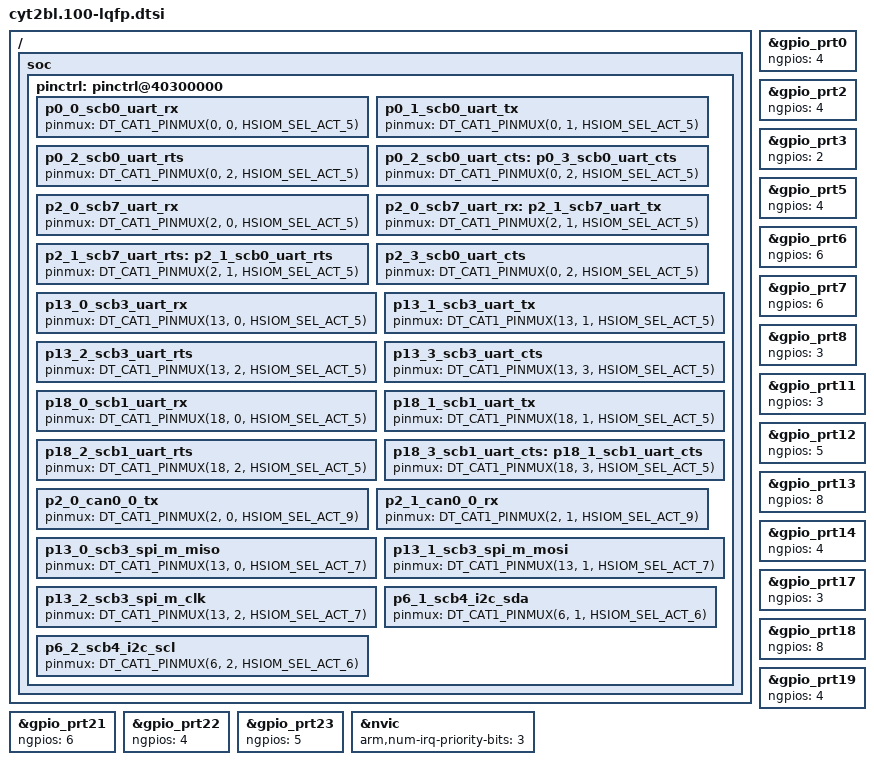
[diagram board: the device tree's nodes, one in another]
/*
 * Copyright (c) 2026 Infineon Technologies AG,
 * or an affiliate of Infineon Technologies AG.
 *
 * SPDX-License-Identifier: Apache-2.0
 */

#include "cyt2bl.dtsi"
#include <arm/armv7-m.dtsi>
#include <zephyr/dt-bindings/gpio/gpio.h>
#include <zephyr/dt-bindings/pinctrl/ifx_cat1-pinctrl.h>


/ {

        soc {
                /delete-node/ gpio@40310080; // gpio_prt1
                /delete-node/ gpio@40310200; // gpio_prt4
                /delete-node/ gpio@40310480; // gpio_prt9
                /delete-node/ gpio@40310500; // gpio_prt10
                /delete-node/ gpio@40310780; // gpio_prt15
                /delete-node/ gpio@40310800; // gpio_prt16
                /delete-node/ gpio@40310A00; // gpio_prt20
				pinctrl: pinctrl@40300000 {
					/omit-if-no-ref/ p0_0_scb0_uart_rx: p0_0_scb0_uart_rx {
								pinmux = <DT_CAT1_PINMUX(0, 0,	HSIOM_SEL_ACT_5)>;
					};
					/omit-if-no-ref/ p0_1_scb0_uart_tx: p0_1_scb0_uart_tx {
								pinmux = <DT_CAT1_PINMUX(0, 1,	HSIOM_SEL_ACT_5)>;
					};
					/omit-if-no-ref/ p0_2_scb0_uart_rts: p0_2_scb0_uart_rts {
								pinmux = <DT_CAT1_PINMUX(0, 2,	HSIOM_SEL_ACT_5)>;
					};
					/omit-if-no-ref/ p0_2_scb0_uart_cts: p0_3_scb0_uart_cts {
								pinmux = <DT_CAT1_PINMUX(0, 2,	HSIOM_SEL_ACT_5)>;
					};
					/omit-if-no-ref/ p2_0_scb7_uart_rx: p2_0_scb7_uart_rx {
								pinmux = <DT_CAT1_PINMUX(2, 0,	HSIOM_SEL_ACT_5)>;
					};
                    /omit-if-no-ref/ p2_0_scb7_uart_rx: p2_1_scb7_uart_tx {
								pinmux = <DT_CAT1_PINMUX(2, 1,	HSIOM_SEL_ACT_5)>;
					};
                    /omit-if-no-ref/ p2_1_scb7_uart_rts: p2_1_scb0_uart_rts {
								pinmux = <DT_CAT1_PINMUX(2, 1,	HSIOM_SEL_ACT_5)>;
					};
					/omit-if-no-ref/ p2_3_scb0_uart_cts: p2_3_scb0_uart_cts {
								pinmux = <DT_CAT1_PINMUX(0, 2,	HSIOM_SEL_ACT_5)>;
					};
					/omit-if-no-ref/ p13_0_scb3_uart_rx: p13_0_scb3_uart_rx {
								pinmux = <DT_CAT1_PINMUX(13, 0, HSIOM_SEL_ACT_5)>;
					};
					/omit-if-no-ref/ p13_1_scb3_uart_tx: p13_1_scb3_uart_tx {
								pinmux = <DT_CAT1_PINMUX(13, 1, HSIOM_SEL_ACT_5)>;
					};
					/omit-if-no-ref/ p13_2_scb3_uart_rts: p13_2_scb3_uart_rts {
								pinmux = <DT_CAT1_PINMUX(13, 2, HSIOM_SEL_ACT_5)>;
					};
					/omit-if-no-ref/ p13_3_scb3_uart_cts: p13_3_scb3_uart_cts {
								pinmux = <DT_CAT1_PINMUX(13, 3, HSIOM_SEL_ACT_5)>;
					};


					/omit-if-no-ref/ p18_0_scb1_uart_rx: p18_0_scb1_uart_rx {
								pinmux = <DT_CAT1_PINMUX(18, 0, HSIOM_SEL_ACT_5)>;
					};
					/omit-if-no-ref/ p18_1_scb1_uart_tx: p18_1_scb1_uart_tx {
								pinmux = <DT_CAT1_PINMUX(18, 1, HSIOM_SEL_ACT_5)>;
					};
					/omit-if-no-ref/ p18_2_scb1_uart_rts: p18_2_scb1_uart_rts {
								pinmux = <DT_CAT1_PINMUX(18, 2, HSIOM_SEL_ACT_5)>;
					};
					/omit-if-no-ref/ p18_3_scb1_uart_cts: p18_1_scb1_uart_cts {
								pinmux = <DT_CAT1_PINMUX(18, 3, HSIOM_SEL_ACT_5)>;
					};


					/omit-if-no-ref/ p2_0_can0_0_tx: p2_0_can0_0_tx {
								pinmux = <DT_CAT1_PINMUX(2, 0, HSIOM_SEL_ACT_9)>;
					};

					/omit-if-no-ref/ p2_1_can0_0_rx: p2_1_can0_0_rx {
								pinmux = <DT_CAT1_PINMUX(2, 1, HSIOM_SEL_ACT_9)>;
					};



					/omit-if-no-ref/ p13_0_scb3_spi_m_miso: p13_0_scb3_spi_m_miso {
								pinmux = <DT_CAT1_PINMUX(13, 0, HSIOM_SEL_ACT_7)>;
					};

					/omit-if-no-ref/ p13_1_scb3_spi_m_mosi: p13_1_scb3_spi_m_mosi {
								pinmux = <DT_CAT1_PINMUX(13, 1, HSIOM_SEL_ACT_7)>;
					};

					/omit-if-no-ref/ p13_2_scb3_spi_m_clk: p13_2_scb3_spi_m_clk {
								pinmux = <DT_CAT1_PINMUX(13, 2, HSIOM_SEL_ACT_7)>;
					};

					/omit-if-no-ref/ p6_1_scb4_i2c_sda: p6_1_scb4_i2c_sda {
								pinmux = <DT_CAT1_PINMUX(6, 1, HSIOM_SEL_ACT_6)>;
					};
					
					/omit-if-no-ref/ p6_2_scb4_i2c_scl: p6_2_scb4_i2c_scl {
								pinmux = <DT_CAT1_PINMUX(6, 2, HSIOM_SEL_ACT_6)>;
					};

					
			
                            };
    };
};

&gpio_prt0 {
	    ngpios = <4>;
};

&gpio_prt2 {
	    ngpios = <4>;
};

&gpio_prt3 {
	    ngpios = <2>;
};

&gpio_prt5 {
	    ngpios = <4>;
};

&gpio_prt6 {
	    ngpios = <6>;
};

&gpio_prt7 {
	    ngpios = <6>;
};

&gpio_prt8 {
	    ngpios = <3>;
};

&gpio_prt11 {
	    ngpios = <3>;
};

&gpio_prt12 {
	    ngpios = <5>;
};

&gpio_prt13 {
	    ngpios = <8>;
};

&gpio_prt14 {
	    ngpios = <4>;
};

&gpio_prt17 {
	    ngpios = <3>;
};

&gpio_prt18 {
	    ngpios = <8>;
};


&gpio_prt19 {
	    ngpios = <4>;
};

&gpio_prt21 {
	    ngpios = <6>;
};

&gpio_prt22 {
	    ngpios = <4>;
};

&gpio_prt23 {
	    ngpios = <5>;
};

&nvic {
	arm,num-irq-priority-bits = <3>;
};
